# XHSC_HC32F420 register map
Vendor: XHSC Co.Ltd; Series: ARMCM4; File version: 1.2
CPU: CM4 r0p0, little endian, no MPU, no FPU, 3 interrupt priority bits
Registers are 32-bit, read-write, reset 0x0 unless marked. A register's access mark holds for its fields unless they carry their own. Offsets are from the block's base; [hi:lo] are bit positions; {n}, {i} and the like mark numbered series.

## ADC0 — desc ADC
Base 0x4000A000
Same registers: ADC1 0x4000A400
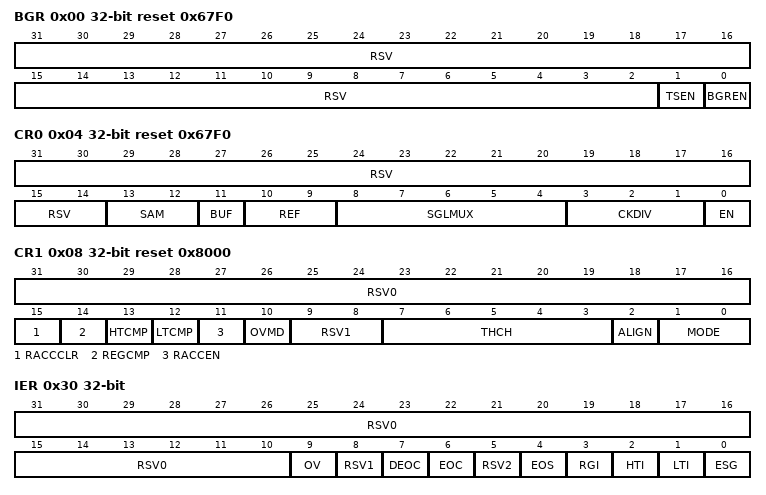
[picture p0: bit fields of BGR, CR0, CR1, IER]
0x00 BGR reset 0x67F0 (reset mask 0xBFFF)
  [31:2] RSV, [1] TSEN, [0] BGREN
0x04 CR0 reset 0x67F0 (reset mask 0xBFFF)
  [31:14] RSV, [13:12] SAM, [11] BUF, [10:9] REF, [8:4] SGLMUX, [3:1] CKDIV, [0] EN
0x08 CR1 reset 0x8000 (reset mask 0xFFFC)
  [31:16] RSV0, [15] RACCCLR, [14] REGCMP, [13] HTCMP, [12] LTCMP, [11] RACCEN, [10] OVMD, [9:8] RSV1, [7:3] THCH, [2] ALIGN, [1:0] MODE
0x30 IER ro (reset mask 0x3F)
  [31:10] RSV0 rw, [9] OV rw, [8] RSV1 rw, [7] DEOC rw, [6] EOC rw, [5] RSV2 rw, [4] EOS rw, [3] RGI rw, [2] HTI rw, [1] LTI rw, [0] ESG rw
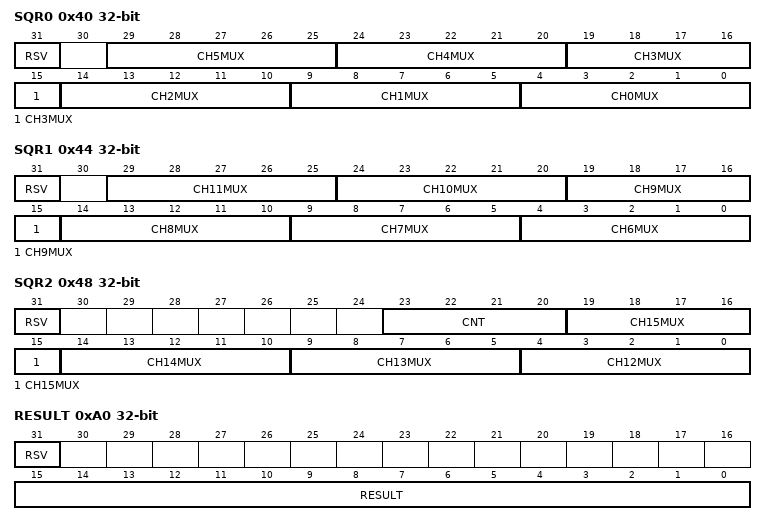
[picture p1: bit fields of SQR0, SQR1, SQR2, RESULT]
0x40 SQR0 (reset mask 0x3FFFFFFF)
  [31] RSV, [5n+4:5n] CH{n}MUX (n=0..5)
0x44 SQR1 (reset mask 0x3FFFFFFF)
  [31] RSV, [5n-26:5n-30] CH{n}MUX (n=6..11)
0x48 SQR2 (reset mask 0xFFFFFFF)
  [31] RSV, [23:20] CNT, [5n-56:5n-60] CH{n}MUX (n=12..15)
0xA0 RESULT ro (reset mask 0xFFF)
  [31] RSV rw, [15:0] RESULT
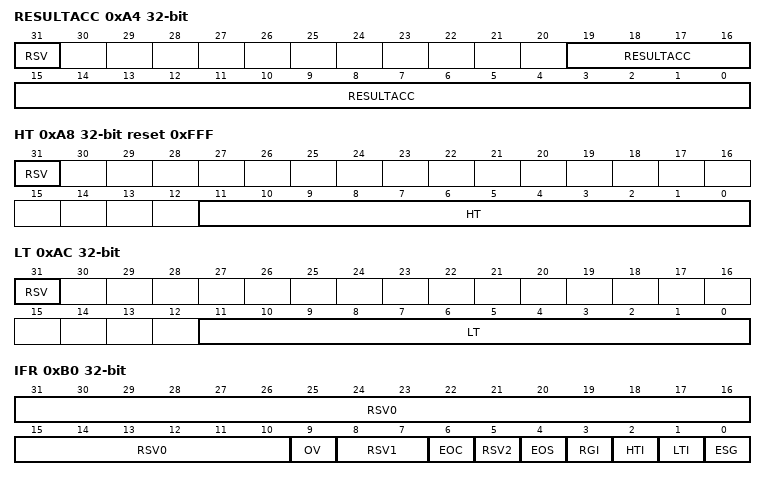
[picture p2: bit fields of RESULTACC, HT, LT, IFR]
0xA4 RESULTACC ro (reset mask 0xFFFFF)
  [31] RSV rw, [19:0] RESULTACC
0xA8 HT reset 0xFFF (reset mask 0xFFF)
  [31] RSV, [11:0] HT
0xAC LT (reset mask 0xFFF)
  [31] RSV, [11:0] LT
0xB0 IFR ro (reset mask 0x3F)
  [31:10] RSV0 rw, [9] OV, [8:7] RSV1, [6] EOC, [5] RSV2, [4] EOS, [3] RGI, [2] HTI, [1] LTI, [0] ESG
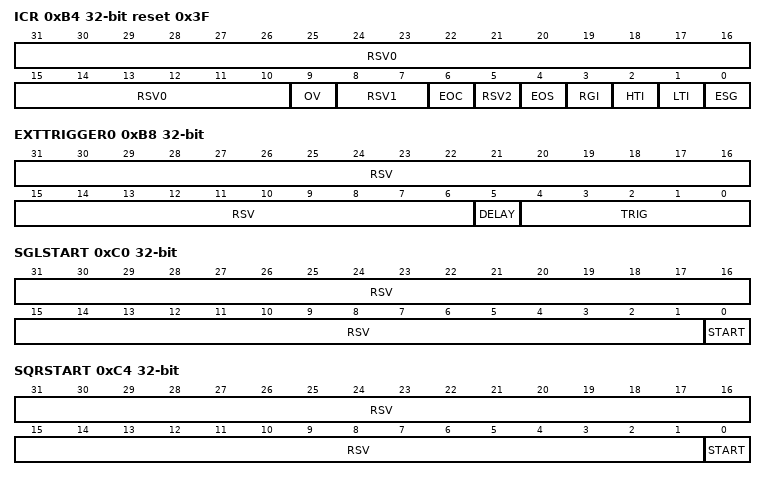
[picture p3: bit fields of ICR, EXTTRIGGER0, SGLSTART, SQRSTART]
0xB4 ICR wo reset 0x3F (reset mask 0x3F)
  [31:10] RSV0 rw, [9] OV rw, [8:7] RSV1 ro, [6] EOC rw, [5] RSV2 rw, [4] EOS rw, [3] RGI rw, [2] HTI rw, [1] LTI rw, [0] ESG rw
0xB8 EXTTRIGGER0
  [31:6] RSV, [5] DELAY, [4:0] TRIG
0xC0 SGLSTART (reset mask 0x1)
  [31:1] RSV, [0] START
0xC4 SQRSTART (reset mask 0x1)
  [31:1] RSV, [0] START

## ATIM0MODE0
Base 0x40006000
Same registers: ATIM3MODE0 0x40006C00
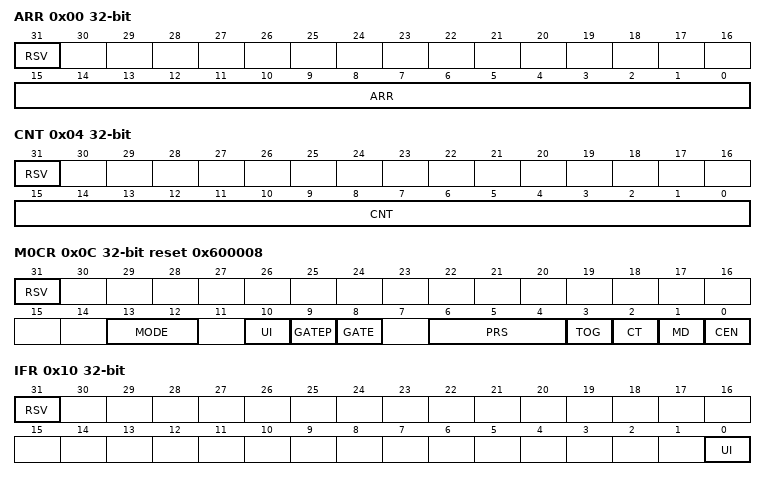
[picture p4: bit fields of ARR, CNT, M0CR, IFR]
0x00 ARR (reset mask 0xFFFF)
  [31] RSV, [15:0] ARR
0x04 CNT (reset mask 0xFFFF)
  [31] RSV, [15:0] CNT
0x08 CNT32
0x0C M0CR reset 0x600008 (reset mask 0x377F)
  [31] RSV, [13:12] MODE, [10] UI, [9] GATEP, [8] GATE, [6:4] PRS, [3] TOG, [2] CT, [1] MD, [0] CEN
0x10 IFR ro (reset mask 0x1)
  [31] RSV, [0] UI
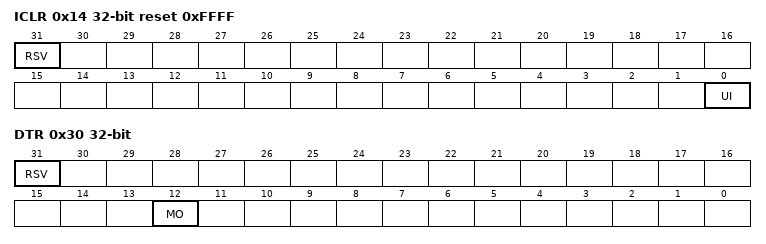
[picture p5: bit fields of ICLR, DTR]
0x14 ICLR reset 0xFFFF (reset mask 0x1)
  [31] RSV, [0] UI
0x30 DTR (reset mask 0x1000)
  [31] RSV, [12] MO

## ATIM0MODE1
Base 0x40006000; alternate view of ATIM0MODE0
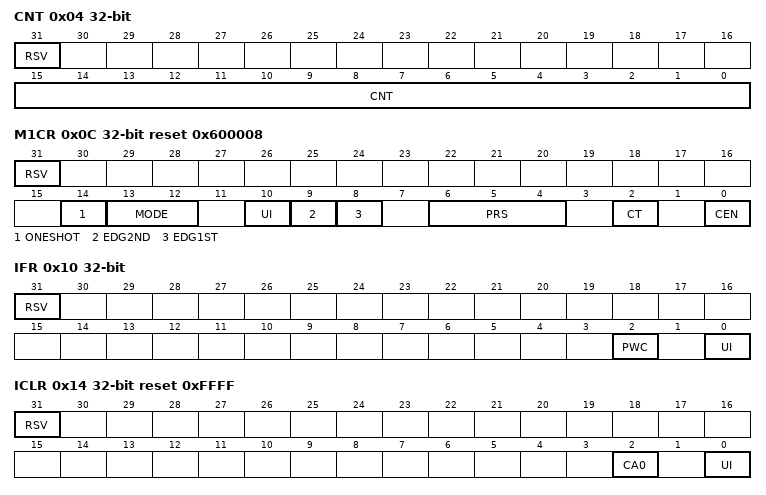
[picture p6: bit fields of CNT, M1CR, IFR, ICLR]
0x04 CNT (reset mask 0xFFFF)
  [31] RSV, [15:0] CNT
0x0C M1CR reset 0x600008 (reset mask 0x7775)
  [31] RSV, [14] ONESHOT, [13:12] MODE, [10] UI, [9] EDG2ND, [8] EDG1ST, [6:4] PRS, [2] CT, [0] CEN
0x10 IFR ro (reset mask 0x5)
  [31] RSV, [2] PWC, [0] UI
0x14 ICLR reset 0xFFFF (reset mask 0x5)
  [31] RSV, [2] CA0, [0] UI
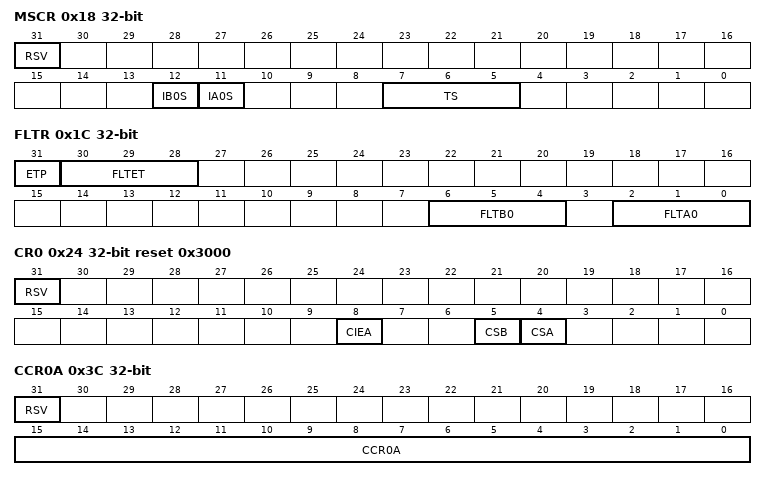
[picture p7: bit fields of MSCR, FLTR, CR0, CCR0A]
0x18 MSCR (reset mask 0x18E0)
  [31] RSV, [12] IB0S, [11] IA0S, [7:5] TS
0x1C FLTR
  [31] ETP, [30:28] FLTET, [6:4] FLTB0, [2:0] FLTA0
0x24 CR0 reset 0x3000 (reset mask 0x100)
  [31] RSV, [8] CIEA, [5] CSB, [4] CSA
0x3C CCR0A ro (reset mask 0xFFFF)
  [31] RSV, [15:0] CCR0A

## ATIM3MODE1
Base 0x40006C00; alternate view of ATIM3MODE0
Registers as ATIM0MODE1.

## ATIM0MODE23
Base 0x40006000; alternate view of ATIM0MODE0
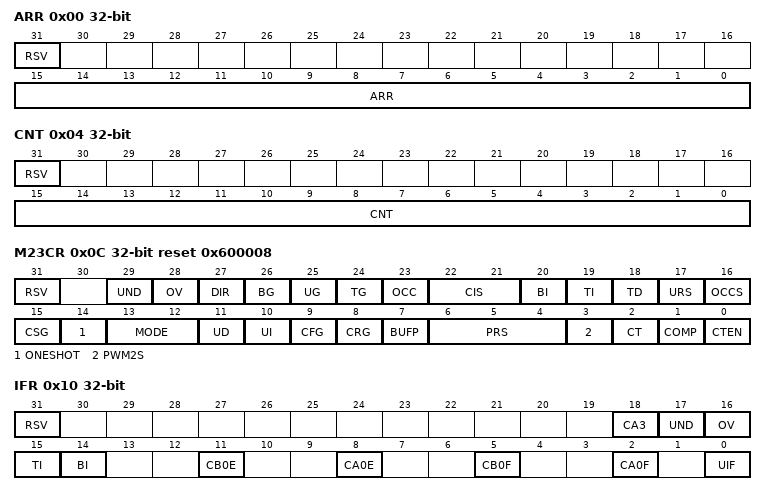
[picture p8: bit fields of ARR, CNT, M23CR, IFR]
0x00 ARR (reset mask 0xFFFF)
  [31] RSV, [15:0] ARR
0x04 CNT (reset mask 0xFFFF)
  [31] RSV, [15:0] CNT
0x0C M23CR reset 0x600008 (reset mask 0xFFFFFFF)
  [31] RSV, [29] UND, [28] OV, [27] DIR, [26] BG wo, [25] UG wo, [24] TG wo, [23] OCC, [22:21] CIS, [20] BI, [19] TI, [18] TD, [17] URS, [16] OCCS, [15] CSG, [14] ONESHOT, [13:12] MODE, [11] UD, [10] UI, [9] CFG, [8] CRG, [7] BUFP, [6:4] PRS, [3] PWM2S, [2] CT, [1] COMP, [0] CTEN
0x10 IFR ro (reset mask 0xFFFD)
  [31] RSV, [18] CA3, [17] UND, [16] OV, [15] TI, [14] BI, [11] CB0E, [8] CA0E, [5] CB0F, [2] CA0F, [0] UIF
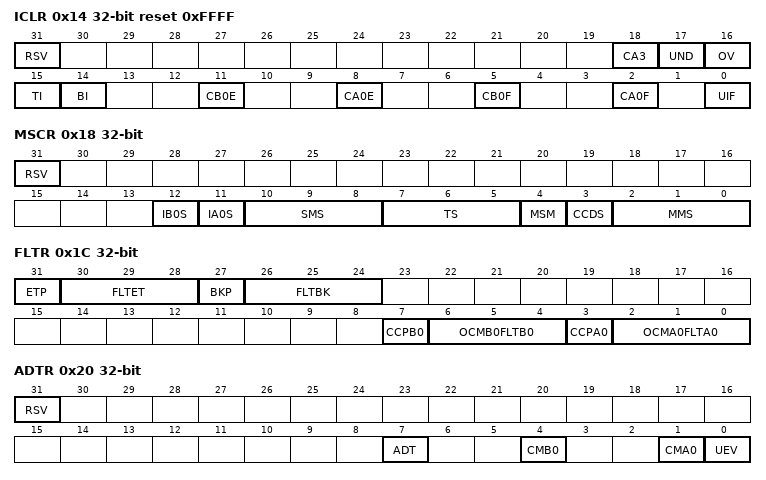
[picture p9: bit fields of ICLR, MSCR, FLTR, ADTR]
0x14 ICLR wo reset 0xFFFF (reset mask 0xFFFD)
  [31] RSV rw, [18] CA3 rw, [17] UND rw, [16] OV rw, [15] TI rw, [14] BI rw, [11] CB0E rw, [8] CA0E rw, [5] CB0F rw, [2] CA0F rw, [0] UIF rw
0x18 MSCR (reset mask 0x1FFF)
  [31] RSV, [12] IB0S, [11] IA0S, [10:8] SMS, [7:5] TS, [4] MSM, [3] CCDS, [2:0] MMS
0x1C FLTR
  [31] ETP, [30:28] FLTET, [27] BKP, [26:24] FLTBK, [7] CCPB0, [6:4] OCMB0FLTB0, [3] CCPA0, [2:0] OCMA0FLTA0
0x20 ADTR (reset mask 0xFF)
  [31] RSV, [7] ADT, [4] CMB0, [1] CMA0, [0] UEV
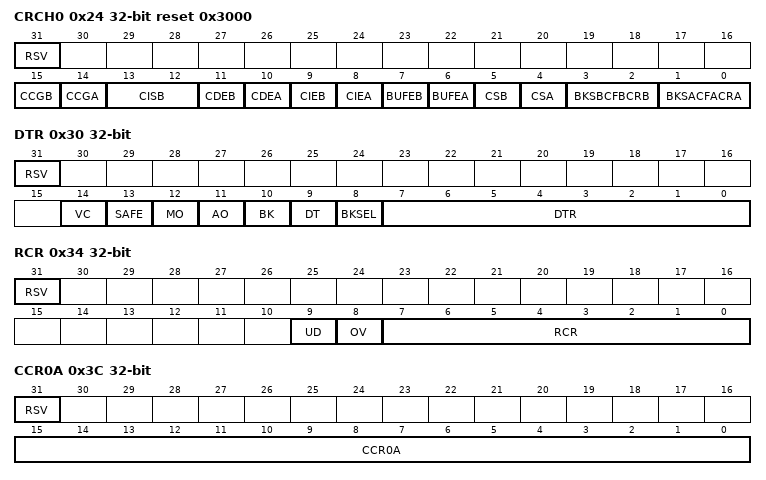
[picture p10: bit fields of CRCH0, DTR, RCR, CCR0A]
0x24 CRCH0 reset 0x3000 (reset mask 0xFFFF)
  [31] RSV, [15] CCGB, [14] CCGA, [13:12] CISB, [11] CDEB, [10] CDEA, [9] CIEB, [8] CIEA, [7] BUFEB, [6] BUFEA, [5] CSB, [4] CSA, [3:2] BKSBCFBCRB, [1:0] BKSACFACRA
0x30 DTR (reset mask 0xFFFF)
  [31] RSV, [14] VC, [13] SAFE, [12] MO, [11] AO, [10] BK, [9] DT, [8] BKSEL, [7:0] DTR
0x34 RCR (reset mask 0xFF)
  [31] RSV, [9] UD, [8] OV, [7:0] RCR
0x3C CCR0A (reset mask 0xFFFF)
  [31] RSV, [15:0] CCR0A
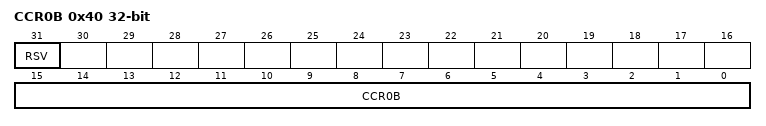
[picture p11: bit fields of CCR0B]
0x40 CCR0B (reset mask 0xFFFF)
  [31] RSV, [15:0] CCR0B
